AUTOSAR XML (schema 00051)
package /Components
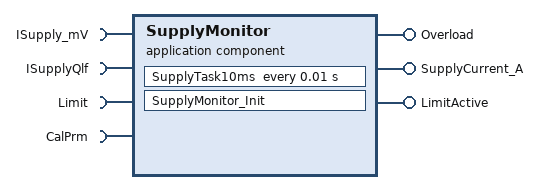
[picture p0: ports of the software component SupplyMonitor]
  application sw component type SupplyMonitor
    require port ISupply_mV: nonqueued-receiver-com-spec{data-element=ISupply_mV, init-value=0}, required-interface=ISupply_mV
    require port ISupplyQlf: nonqueued-receiver-com-spec{data-element=ISupplyQlf, init-value=0}, required-interface=ISupplyQlf
    require port Limit: nonqueued-receiver-com-spec{data-element=Limit, init-value=0}, required-interface=Limit
    provide port Overload: nonqueued-sender-com-spec{data-element=Overload, init-value=0}, provided-interface=Overload
    provide port SupplyCurrent_A: nonqueued-sender-com-spec{data-element=SupplyCurrent_A, init-value=0}, provided-interface=SupplyCurrent_A
    provide port LimitActive: nonqueued-sender-com-spec{data-element=LimitActive, init-value=0}, provided-interface=LimitActive
    require port CalPrm: required-interface=CalPrm
      required-com-specs:
        init-value=CalPrm_OverloadHyst_mA:200, parameter=OverloadHyst_mA
        init-value=CalPrm_OverloadThd_mA:1280, parameter=OverloadThd_mA
        init-value=CalPrm_SupplyCurrentFilter:0.0078125, parameter=SupplyCurrentFilter
        init-value=CalPrm_SupplyCurrentGain:1, parameter=SupplyCurrentGain
    behavior SupplyMonitor_IB: handle-termination-and-restart=NO-SUPPORT
      timing event Event_SupplyTask10ms: start-on-event=SupplyTask10ms, period=0.01
      runnable SupplyMonitor_Init
      runnable SupplyTask10ms
        data-receive-point-by-arguments:
          access IN_ISupplyQlf_ISupplyQlf: accessed-variable=ISupplyQlf.ISupplyQlf
          access IN_ISupply_mV_ISupply_mV: accessed-variable=ISupply_mV.ISupply_mV
          access IN_Limit_Limit: accessed-variable=Limit.Limit
        data-send-points:
          access OUT_Overload_Overload: accessed-variable=Overload.Overload
          access OUT_SupplyCurrent_A_SupplyCurrent_A: accessed-variable=SupplyCurrent_A.SupplyCurrent_A
          access OUT_LimitActive_LimitActive: accessed-variable=LimitActive.LimitActive
        4 x parameter access:
          CALPRM_CalPrm_OverloadHyst_mA: accessed-parameter=CalPrm.OverloadHyst_mA
          CALPRM_CalPrm_OverloadThd_mA: accessed-parameter=CalPrm.OverloadThd_mA
          CALPRM_CalPrm_SupplyCurrentFilter: accessed-parameter=CalPrm.SupplyCurrentFilter
          CALPRM_CalPrm_SupplyCurrentGain: accessed-parameter=CalPrm.SupplyCurrentGain
